# ESP32-C61 register map
Vendor: ESPRESSIF SYSTEMS (SHANGHAI) CO., LTD.; Series: ESP32 C-Series; File version: 1
CPU: RV32IMAC r0p0, little endian, no MPU, no FPU, 0 interrupt priority bits
Address unit: 32 bits
Registers are 32-bit, read-write, reset 0x0 unless marked. A register's access mark holds for its fields unless they carry their own. Offsets are from the block's base; [hi:lo] are bit positions; {n}, {i} and the like mark numbered series.

## INTPRI — INTPRI Peripheral
Base 0x600C5000
{0x90+4i} CPU_INTR_FROM_CPU{i} (i=0..3) — CPU_INTR_FROM_CPU{i} mapping register
  [0] CPU_INTR_FROM_CPU — CPU_INTR_FROM_CPU_%s mapping register.
0xA0 DATE reset 0x2303150 — Version control register
  [27:0] DATE — Version control register.
0xA4 CLOCK_GATE reset 0x1 — register description
  [0] CLK_EN — Need add description
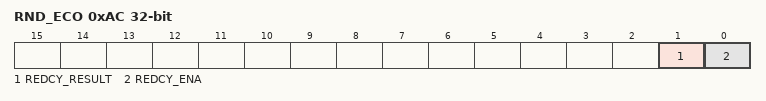
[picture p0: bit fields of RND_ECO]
0xAC RND_ECO access per field — redcy eco register.
  [1] REDCY_RESULT ro — Only reserved for ECO.
  [0] REDCY_ENA rw — Only reserved for ECO.
0xB0 RND_ECO_LOW — redcy eco low register.
  [31:0] REDCY_LOW — Only reserved for ECO.
0x3FC RND_ECO_HIGH reset 0xFFFFFFFF — redcy eco high register.
  [31:0] REDCY_HIGH — Only reserved for ECO.

## LPPERI — LPPERI Peripheral
Base 0x600B2800
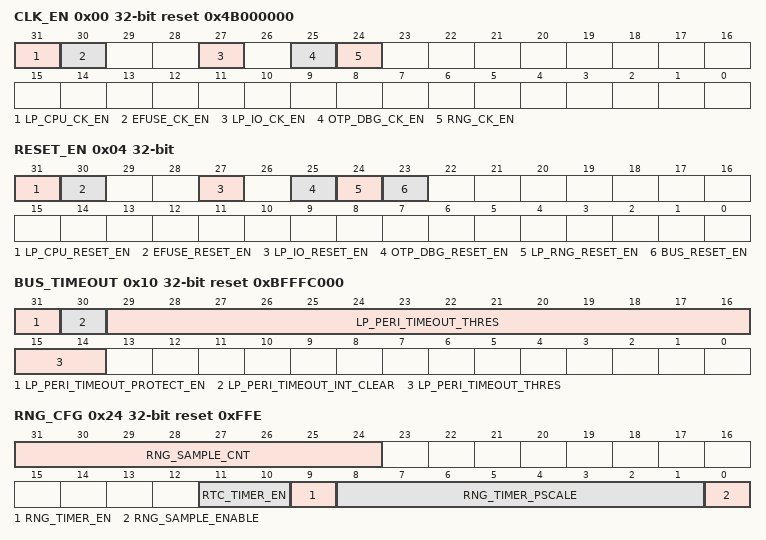
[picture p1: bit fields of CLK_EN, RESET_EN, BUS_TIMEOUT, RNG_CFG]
0x00 CLK_EN reset 0x4B000000 — need_des
  [31] LP_CPU_CK_EN — need_des
  [30] EFUSE_CK_EN — need_des
  [27] LP_IO_CK_EN — need_des
  [25] OTP_DBG_CK_EN — need_des
  [24] RNG_CK_EN — need_des
0x04 RESET_EN access per field — need_des
  [31] LP_CPU_RESET_EN wo — need_des
  [30] EFUSE_RESET_EN rw — need_des
  [27] LP_IO_RESET_EN rw — need_des
  [25] OTP_DBG_RESET_EN rw — need_des
  [24] LP_RNG_RESET_EN rw — need_des
  [23] BUS_RESET_EN wo — need_des
0x08 RNG_DATA ro — need_des
  [31:0] RND_DATA
0x0C CPU reset 0x80000000 — need_des
  [31] LPCORE_DBGM_UNAVALIABLE
0x10 BUS_TIMEOUT access per field reset 0xBFFFC000 — need_des
  [31] LP_PERI_TIMEOUT_PROTECT_EN rw — need_des
  [30] LP_PERI_TIMEOUT_INT_CLEAR wo — need_des
  [29:14] LP_PERI_TIMEOUT_THRES rw — need_des
0x14 BUS_TIMEOUT_ADDR ro — need_des
  [31:0] LP_PERI_TIMEOUT_ADDR
0x18 BUS_TIMEOUT_UID ro — need_des
  [6:0] LP_PERI_TIMEOUT_UID
0x20 INTERRUPT_SOURCE ro — need_des
  [5:0] LP_INTERRUPT_SOURCE — BIT5~BIT0: pmu_lp_int, modem_lp_int, lp_timer_lp_int, reserved, reserved, lp_io_int
0x24 RNG_CFG access per field reset 0xFFE — need_des
  [31:24] RNG_SAMPLE_CNT ro — need des
  [11:10] RTC_TIMER_EN rw — need des
  [9] RNG_TIMER_EN rw — need des
  [8:1] RNG_TIMER_PSCALE rw — need des
  [0] RNG_SAMPLE_ENABLE rw — need des
0x28 RNG_DATA_SYNC ro — need_des
  [31:0] RND_SYNC_DATA
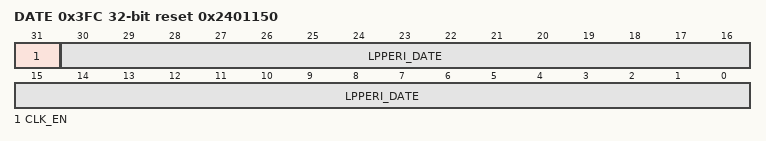
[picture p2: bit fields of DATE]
0x3FC DATE reset 0x2401150 — need_des
  [31] CLK_EN — need_des
  [30:0] LPPERI_DATE — need_des

## LP_ANA — LP_ANA Peripheral
Base 0x600B2C00
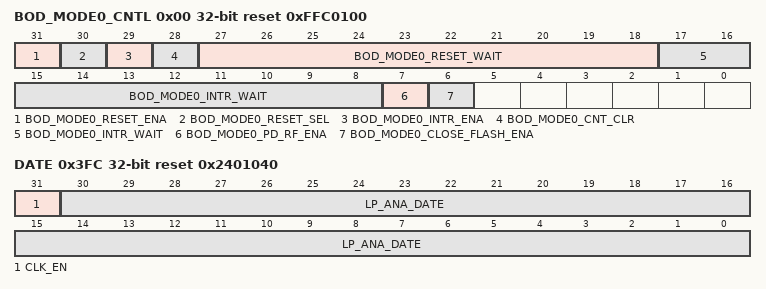
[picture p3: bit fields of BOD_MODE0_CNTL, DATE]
0x00 BOD_MODE0_CNTL reset 0xFFC0100 — need_des
  [31] BOD_MODE0_RESET_ENA — need_des
  [30] BOD_MODE0_RESET_SEL — need_des
  [29] BOD_MODE0_INTR_ENA — need_des
  [28] BOD_MODE0_CNT_CLR — need_des
  [27:18] BOD_MODE0_RESET_WAIT — need_des
  [17:8] BOD_MODE0_INTR_WAIT — need_des
  [7] BOD_MODE0_PD_RF_ENA — need_des
  [6] BOD_MODE0_CLOSE_FLASH_ENA — need_des
0x04 BOD_MODE1_CNTL — need_des
  [31] BOD_MODE1_RESET_ENA
0x08 POWER_GLITCH_CNTL — need_des
  [31:28] POWER_GLITCH_RESET_ENA
0x0C FIB_ENABLE reset 0xFFFFFFFF — need_des
  [31:0] ANA_FIB_ENA
0x10 INT_RAW — need_des
  [31] BOD_MODE0_INT_RAW
0x14 INT_ST ro — need_des
  [31] BOD_MODE0_INT_ST
0x18 INT_ENA — need_des
  [31] BOD_MODE0_INT_ENA
0x1C INT_CLR wo — need_des
  [31] BOD_MODE0_INT_CLR
0x20 LP_INT_RAW — need_des
  [31] BOD_MODE0_LP_INT_RAW
0x24 LP_INT_ST ro — need_des
  [31] BOD_MODE0_LP_INT_ST
0x28 LP_INT_ENA — need_des
  [31] BOD_MODE0_LP_INT_ENA
0x2C LP_INT_CLR wo — need_des
  [31] BOD_MODE0_LP_INT_CLR
0x3FC DATE reset 0x2401040 — need_des
  [31] CLK_EN — need_des
  [30:0] LP_ANA_DATE — need_des

## LP_AON — LP_AON Peripheral
Base 0x600B1000
{0x0+4i} STORE{i} (i=0..9) — need_des
  [31:0] LP_AON_STORE{i}
0x28 GPIO_MUX — need_des
  [7:0] SEL
0x2C GPIO_HOLD0 — need_des
0x30 GPIO_HOLD1 — need_des
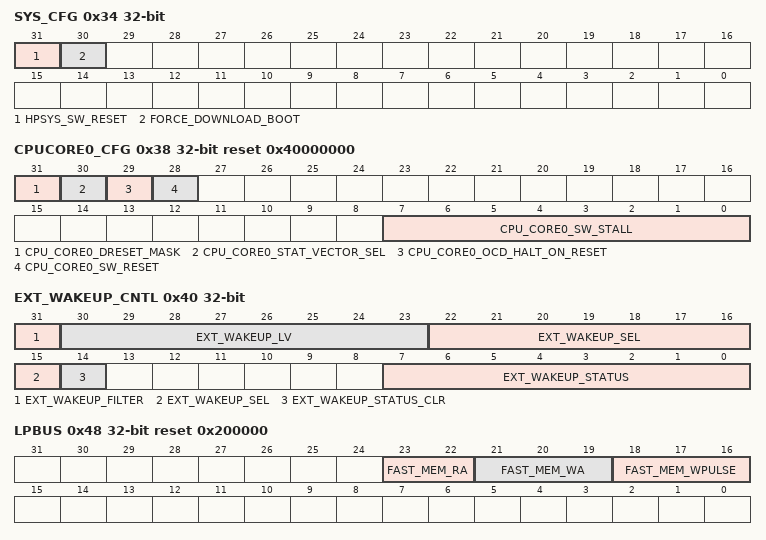
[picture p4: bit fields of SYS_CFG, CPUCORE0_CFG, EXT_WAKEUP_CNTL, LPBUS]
0x34 SYS_CFG access per field — need_des
  [31] HPSYS_SW_RESET wo — need_des
  [30] FORCE_DOWNLOAD_BOOT rw — need_des
0x38 CPUCORE0_CFG access per field reset 0x40000000 — need_des
  [31] CPU_CORE0_DRESET_MASK rw — need_des
  [30] CPU_CORE0_STAT_VECTOR_SEL rw — need_des
  [29] CPU_CORE0_OCD_HALT_ON_RESET rw — need_des
  [28] CPU_CORE0_SW_RESET wo — need_des
  [7:0] CPU_CORE0_SW_STALL rw — need_des
0x3C IO_MUX — need_des
  [31] RESET_DISABLE
0x40 EXT_WAKEUP_CNTL access per field — need_des
  [31] EXT_WAKEUP_FILTER rw — need_des
  [30:23] EXT_WAKEUP_LV rw — need_des
  [22:15] EXT_WAKEUP_SEL rw — need_des
  [14] EXT_WAKEUP_STATUS_CLR wo — need_des
  [7:0] EXT_WAKEUP_STATUS ro — need_des
0x44 USB — need_des
  [31] RESET_DISABLE
0x48 LPBUS reset 0x200000 — need_des
  [23:22] FAST_MEM_RA — This field controls fast memory RA parameter.
  [21:19] FAST_MEM_WA — This field controls fast memory WA parameter.
  [18:16] FAST_MEM_WPULSE — This field controls fast memory WPULSE parameter.
0x4C SDIO_ACTIVE reset 0x2800000 — need_des
  [31:22] SDIO_ACT_DNUM
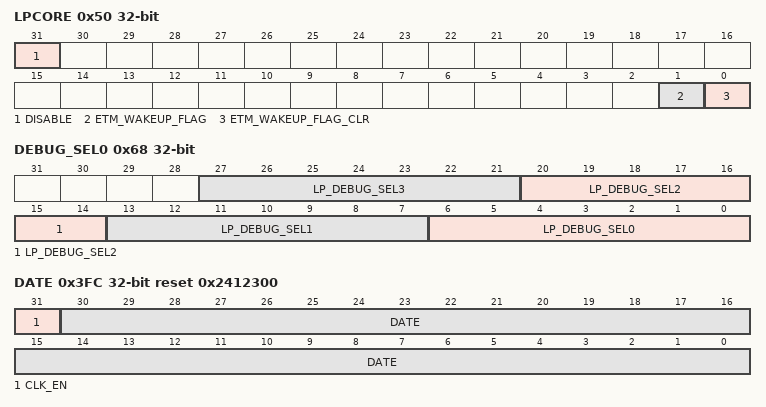
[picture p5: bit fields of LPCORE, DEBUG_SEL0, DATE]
0x50 LPCORE access per field — need_des
  [31] DISABLE rw — need_des
  [1] ETM_WAKEUP_FLAG rw — need_des
  [0] ETM_WAKEUP_FLAG_CLR wo — need_des
0x54 SAR_CCT — need_des
  [31:29] SAR2_PWDET_CCT
0x58 MODEM_BUS — need_des
  [31] MODEM_SYNC_BRIDGE_EN
0x60 SPRAM_CTRL reset 0x2070 — need_des
  [31:0] SPRAM_MEM_AUX_CTRL
0x64 SPRF_CTRL reset 0x2070 — need_des
  [31:0] SPRF_MEM_AUX_CTRL
0x68 DEBUG_SEL0 — need des
  [7n+6:7n] LP_DEBUG_SEL{n} (n=0..3) — need des
0x6C DEBUG_SEL1 — need des
  [6:0] LP_DEBUG_SEL4
0x3FC DATE reset 0x2412300 — need_des
  [31] CLK_EN — need_des
  [30:0] DATE — need_des
